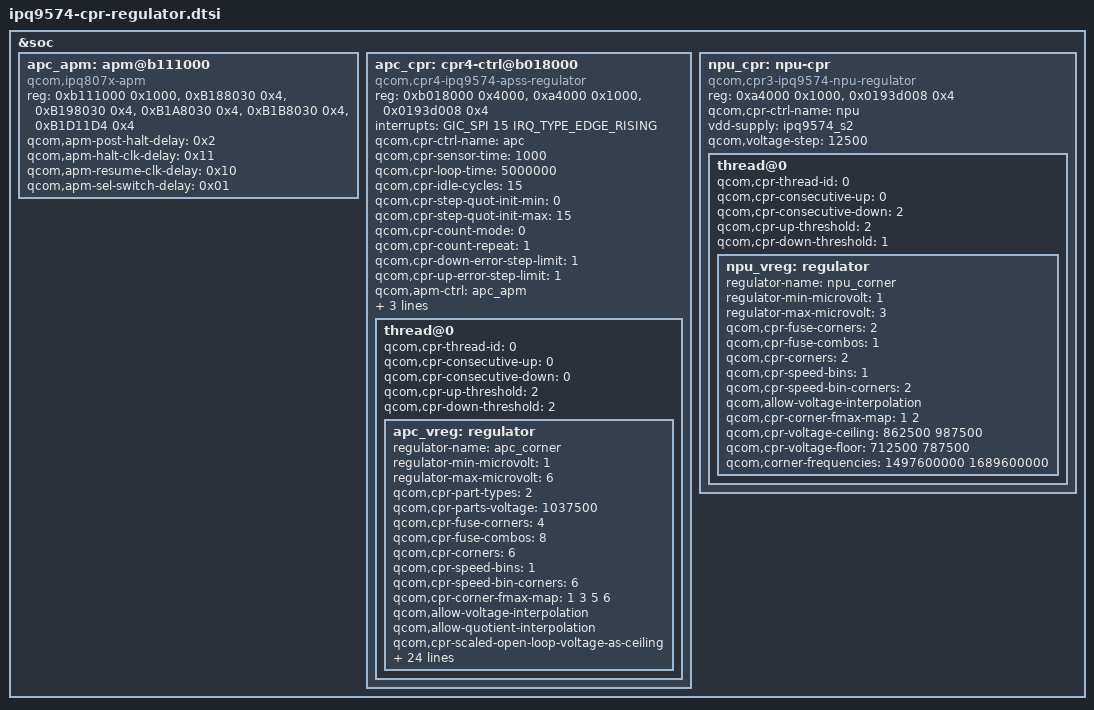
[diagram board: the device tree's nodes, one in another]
/*
 * Copyright (c) 2017, 2021 The Linux Foundation. All rights reserved.
 *
 * Permission to use, copy, modify, and/or distribute this software for any
 * purpose with or without fee is hereby granted, provided that the above
 * copyright notice and this permission notice appear in all copies.
 *
 * THE SOFTWARE IS PROVIDED "AS IS" AND THE AUTHOR DISCLAIMS ALL WARRANTIES
 * WITH REGARD TO THIS SOFTWARE INCLUDING ALL IMPLIED WARRANTIES OF
 * MERCHANTABILITY AND FITNESS. IN NO EVENT SHALL THE AUTHOR BE LIABLE FOR
 * ANY SPECIAL, DIRECT, INDIRECT, OR CONSEQUENTIAL DAMAGES OR ANY DAMAGES
 * WHATSOEVER RESULTING FROM LOSS OF USE, DATA OR PROFITS, WHETHER IN AN
 * ACTION OF CONTRACT, NEGLIGENCE OR OTHER TORTIOUS ACTION, ARISING OUT OF
 * OR IN CONNECTION WITH THE USE OR PERFORMANCE OF THIS SOFTWARE.
 */

&soc {
	apc_apm: apm@b111000 {
		compatible = "qcom,ipq807x-apm";
		reg = <0xb111000 0x1000>,
		      <0xB188030 0x4>,
		      <0xB198030 0x4>,
		      <0xB1A8030 0x4>,
		      <0xB1B8030 0x4>,
		      <0xB1D11D4 0x4>;
		reg-names = "pm-apcc-glb",
			    "alias0-pwr-gate",
			    "alias1-pwr-gate",
			    "alias2-pwr-gate",
			    "alias3-pwr-gate",
			    "apm-ctl-override";
		qcom,apm-post-halt-delay = <0x2>;
		qcom,apm-halt-clk-delay = <0x11>;
		qcom,apm-resume-clk-delay = <0x10>;
		qcom,apm-sel-switch-delay = <0x01>;
	};

	apc_cpr: cpr4-ctrl@b018000 {
		compatible = "qcom,cpr4-ipq9574-apss-regulator";
		reg = <0xb018000 0x4000>, <0xa4000 0x1000>, <0x0193d008 0x4>;
		reg-names = "cpr_ctrl", "fuse_base", "cpr_tcsr_reg";
		interrupts = <GIC_SPI 15 IRQ_TYPE_EDGE_RISING>;
		interrupt-names = "cpr";
		qcom,cpr-ctrl-name = "apc";
		qcom,cpr-sensor-time = <1000>;
		qcom,cpr-loop-time = <5000000>;
		qcom,cpr-idle-cycles = <15>;
		qcom,cpr-step-quot-init-min = <0>;
		qcom,cpr-step-quot-init-max = <15>;
		qcom,cpr-count-mode = <0>;		/* All-at-once */
		qcom,cpr-count-repeat = <1>;
		qcom,cpr-down-error-step-limit = <1>;
		qcom,cpr-up-error-step-limit = <1>;
		qcom,apm-ctrl = <&apc_apm>;
		qcom,apm-threshold-voltage = <850000>;
		vdd-supply = <&ipq9574_s1>;
		qcom,voltage-step = <12500>;

		thread@0 {
			qcom,cpr-thread-id = <0>;
			qcom,cpr-consecutive-up = <0>;
			qcom,cpr-consecutive-down = <0>;
			qcom,cpr-up-threshold = <2>;
			qcom,cpr-down-threshold = <2>;

			apc_vreg: regulator {
				regulator-name = "apc_corner";
				regulator-min-microvolt = <1>;
				regulator-max-microvolt = <6>;
				qcom,cpr-part-types = <2>;
				qcom,cpr-parts-voltage = <1037500>;
				qcom,cpr-fuse-corners = <4>;
				qcom,cpr-fuse-combos = <8>;
				qcom,cpr-corners = <6>;
				qcom,cpr-speed-bins = <1>;
				qcom,cpr-speed-bin-corners = <6>;
				qcom,cpr-corner-fmax-map = <1 3 5 6>;
				qcom,allow-voltage-interpolation;
				qcom,allow-quotient-interpolation;
				qcom,cpr-scaled-open-loop-voltage-as-ceiling;
				qcom,cpr-voltage-ceiling =
					<725000 787500 862500
					 925000 987500 1062500>;
				qcom,cpr-voltage-floor =
					<600000 650000 712500
					 750000 787500 850000>;
				qcom,corner-frequencies =
					<936000000 1104000000 1416000000
					1608000000 1800000000 2208000000>;

				/* TT/FF parts i.e. turbo L1 OL voltage < 1037.5 mV */
				qcom,cpr-open-loop-voltage-fuse-adjustment-0 =
					/* Speed bin 0; CPR rev 0..7 */
					<     0      0      0     0>,
					< 50000      0      0     0>,
					<     0      0      0     0>,
					<     0      0      0     0>,
					<     0      0      0     0>,
					<     0      0      0     0>,
					<     0      0      0     0>,
					<     0      0      0     0>;

				/* SS parts i.e turbo L1 OL voltage >= 1037.5 mV */
				qcom,cpr-open-loop-voltage-fuse-adjustment-1 =
					/* Speed bin 0; CPR rev 0..7 */
					<     0      0      0     0>,
					<     0      0      0     0>,
					<     0      0      0     0>,
					<     0      0      0     0>,
					<     0      0      0     0>,
					<     0      0      0     0>,
					<     0      0      0     0>,
					<     0      0      0     0>;

				/* TT/FF parts i.e. turbo L1 OL voltage < 1037.5 mV */
				qcom,cpr-closed-loop-voltage-fuse-adjustment-0 =
					/* Speed bin 0; CPR rev 0..7 */
					<     0      0      0     0>,
					< 50000      0      0     0>,
					<     0      0      0     0>,
					<     0      0      0     0>,
					<     0      0      0     0>,
					<     0      0      0     0>,
					<     0      0      0     0>,
					<     0      0      0     0>;

				/* SS parts i.e turbo L1 OL voltage >= 1037.5 mV */
				qcom,cpr-closed-loop-voltage-fuse-adjustment-1 =
					/* Speed bin 0; CPR rev 0..7 */
					<     0      0      0     0>,
					<     0      0      0     0>,
					<     0      0      0     0>,
					<     0      0      0     0>,
					<     0      0      0     0>,
					<     0      0      0     0>,
					<     0      0      0     0>,
					<     0      0      0     0>;

				qcom,cpr-ro-scaling-factor =
					< 2383 2112 2250 1502 2269 2055 2046 1949
					  2128 1945 2282 2061 2010 2216 2054 2332 >,
					< 2383 2112 2250 1502 2269 2055 2046 1949
					  2128 1945 2282 2061 2010 2216 2054 2332 >,
					< 2383 2112 2250 1502 2269 2055 2046 1949
					  2128 1945 2282 2061 2010 2216 2054 2332 >,
					< 2383 2112 2250 1502 2269 2055 2046 1949
					  2128 1945 2282 2061 2010 2216 2054 2332 >;

				regulator-always-on;
			};
		};
	};

	npu_cpr: npu-cpr {
		compatible = "qcom,cpr3-ipq9574-npu-regulator";
		reg = <0xa4000 0x1000>, <0x0193d008 0x4>;
		reg-names = "fuse_base", "cpr_tcsr_reg";
		qcom,cpr-ctrl-name = "npu";
		vdd-supply = <&ipq9574_s2>;
		qcom,voltage-step = <12500>;
		thread@0 {
			qcom,cpr-thread-id = <0>;
			qcom,cpr-consecutive-up = <0>;
			qcom,cpr-consecutive-down = <2>;
			qcom,cpr-up-threshold = <2>;
			qcom,cpr-down-threshold = <1>;

			npu_vreg: regulator {
				regulator-name = "npu_corner";
				regulator-min-microvolt = <1>;
				regulator-max-microvolt = <3>;
				qcom,cpr-fuse-corners = <2>;
				qcom,cpr-fuse-combos = <1>;
				qcom,cpr-corners = <2>;
				qcom,cpr-speed-bins = <1>;
				qcom,cpr-speed-bin-corners = <2>;
				qcom,allow-voltage-interpolation;
				qcom,cpr-corner-fmax-map = <1 2>;
				qcom,cpr-voltage-ceiling =
					<862500 987500>;
				qcom,cpr-voltage-floor =
					<712500 787500>;
				qcom,corner-frequencies =
					<1497600000 1689600000>;
			};
		};
	};
};
